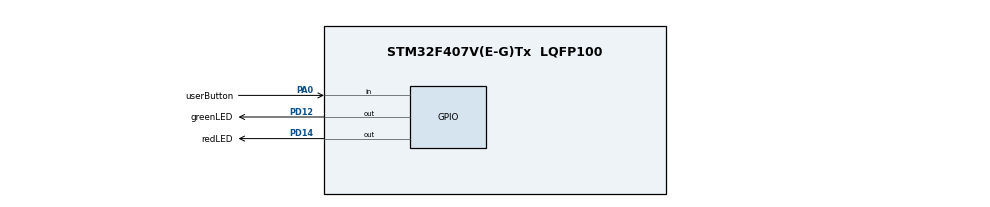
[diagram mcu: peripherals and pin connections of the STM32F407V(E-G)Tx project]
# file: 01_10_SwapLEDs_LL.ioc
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Mcu.Family=STM32F4
Mcu.Name=STM32F407V(E-G)Tx
Mcu.Package=LQFP100
NVIC.PriorityGroup=NVIC_PRIORITYGROUP_4
PA0-WKUP.GPIO_Label=userButton
PA0-WKUP.Signal=GPIO_Input
PD12.GPIO_Label=greenLED
PD12.Signal=GPIO_Output
PD14.GPIO_Label=redLED
PD14.Signal=GPIO_Output
ProjectManager.HeapSize=0x200
ProjectManager.StackSize=0x400
ProjectManager.TargetToolchain=STM32CubeIDE
RCC.AHBFreq_Value=16000000
RCC.APB1Freq_Value=16000000
RCC.APB2Freq_Value=16000000
RCC.CortexFreq_Value=16000000
RCC.HSE_VALUE=25000000
RCC.HSI_VALUE=16000000
RCC.LSE_VALUE=32768
RCC.SYSCLKFreq_VALUE=16000000
RCC.VCOOutputFreq_Value=192000000
board=custom

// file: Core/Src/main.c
/* USER CODE BEGIN Header */
/**
  ******************************************************************************
  * @file           : main.c
  * @brief          : Main program body
  ******************************************************************************
  * @attention
  *
  * Copyright (c) 2024 STMicroelectronics.
  * All rights reserved.
  *
  * This software is licensed under terms that can be found in the LICENSE file
  * in the root directory of this software component.
  * If no LICENSE file comes with this software, it is provided AS-IS.
  *
  ******************************************************************************
  */
/* USER CODE END Header */
#include "main.h"

void SystemClock_Config(void);
static void MX_GPIO_Init(void);

int main(void)
{

  /* USER CODE BEGIN 1 */
	uint16_t b1State = 0;
	uint16_t last = b1State;
	uint16_t ledState = 0;
  /* USER CODE END 1 */

  /* MCU Configuration--------------------------------------------------------*/

  /* Reset of all peripherals, Initializes the Flash interface and the Systick. */
  LL_APB2_GRP1_EnableClock(LL_APB2_GRP1_PERIPH_SYSCFG);
  LL_APB1_GRP1_EnableClock(LL_APB1_GRP1_PERIPH_PWR);

  /* System interrupt init*/
  NVIC_SetPriorityGrouping(NVIC_PRIORITYGROUP_4);

  /* SysTick_IRQn interrupt configuration */
  NVIC_SetPriority(SysTick_IRQn, NVIC_EncodePriority(NVIC_GetPriorityGrouping(),15, 0));

  /* Configure the system clock */
  SystemClock_Config();

  /* Initialize all configured peripherals */
  MX_GPIO_Init();
  /* USER CODE BEGIN 2 */
  LL_GPIO_WriteOutputPort(redLED_GPIO_Port, redLED_Pin);
  /* USER CODE END 2 */

  /* Infinite loop */
  /* USER CODE BEGIN WHILE */
  while (1)
  {
	  b1State = LL_GPIO_ReadInputPort(userButton_GPIO_Port) & userButton_Pin;
	  ledState = LL_GPIO_ReadOutputPort(greenLED_GPIO_Port);
	  if(b1State == 1 && last != b1State){
		  ledState ^= greenLED_Pin | redLED_Pin;
	  }
	  LL_GPIO_WriteOutputPort(redLED_GPIO_Port, ledState);
	  LL_mDelay(5);
	  last = b1State;

    /* USER CODE END WHILE */

  }
}

void SystemClock_Config(void)
{
  LL_FLASH_SetLatency(LL_FLASH_LATENCY_0);
  while(LL_FLASH_GetLatency()!= LL_FLASH_LATENCY_0)
  {
  }
  LL_PWR_SetRegulVoltageScaling(LL_PWR_REGU_VOLTAGE_SCALE1);
  LL_RCC_HSI_SetCalibTrimming(16);
  LL_RCC_HSI_Enable();

   /* Wait till HSI is ready */
  while(LL_RCC_HSI_IsReady() != 1)
  {

  }
  LL_RCC_SetAHBPrescaler(LL_RCC_SYSCLK_DIV_1);
  LL_RCC_SetAPB1Prescaler(LL_RCC_APB1_DIV_1);
  LL_RCC_SetAPB2Prescaler(LL_RCC_APB2_DIV_1);
  LL_RCC_SetSysClkSource(LL_RCC_SYS_CLKSOURCE_HSI);

   /* Wait till System clock is ready */
  while(LL_RCC_GetSysClkSource() != LL_RCC_SYS_CLKSOURCE_STATUS_HSI)
  {

  }
  LL_Init1msTick(16000000);
  LL_SetSystemCoreClock(16000000);
}

static void MX_GPIO_Init(void)
{
  LL_GPIO_InitTypeDef GPIO_InitStruct = {0};

  /* GPIO Ports Clock Enable */
  LL_AHB1_GRP1_EnableClock(LL_AHB1_GRP1_PERIPH_GPIOA);
  LL_AHB1_GRP1_EnableClock(LL_AHB1_GRP1_PERIPH_GPIOD);

  /**/
  LL_GPIO_ResetOutputPin(GPIOD, greenLED_Pin|redLED_Pin);

  /**/
  GPIO_InitStruct.Pin = userButton_Pin;
  GPIO_InitStruct.Mode = LL_GPIO_MODE_INPUT;
  GPIO_InitStruct.Pull = LL_GPIO_PULL_NO;
  LL_GPIO_Init(userButton_GPIO_Port, &GPIO_InitStruct);

  /**/
  GPIO_InitStruct.Pin = greenLED_Pin|redLED_Pin;
  GPIO_InitStruct.Mode = LL_GPIO_MODE_OUTPUT;
  GPIO_InitStruct.Speed = LL_GPIO_SPEED_FREQ_LOW;
  GPIO_InitStruct.OutputType = LL_GPIO_OUTPUT_PUSHPULL;
  GPIO_InitStruct.Pull = LL_GPIO_PULL_NO;
  LL_GPIO_Init(GPIOD, &GPIO_InitStruct);

}

void Error_Handler(void)
{
  __disable_irq();
  while (1)
  {
  }
}
